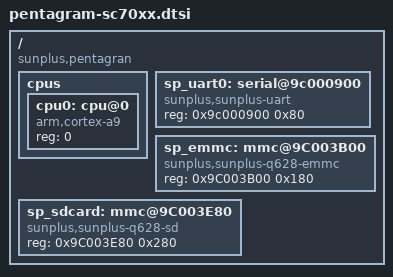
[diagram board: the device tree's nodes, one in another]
/*
 * Sunplus Pentagram sc70xx DTS
 *
 * SPDX-License-Identifier:	GPL-2.0+
 */

/ {
	#address-cells = <1>;
	#size-cells = <1>;
	compatible = "sunplus,pentagran";

	cpus {
		#address-cells = <1>;
		#size-cells = <0>;

		cpu0: cpu@0 {
			compatible = "arm,cortex-a9";
			device_type = "cpu";
			reg = <0>;
		};
	};

	sp_uart0: serial@9c000900 {
		compatible = "sunplus,sunplus-uart";
		reg = <0x9c000900 0x80>;
	};

	sp_emmc: mmc@9C003B00 {
		compatible = "sunplus,sunplus-q628-emmc";
		reg = <0x9C003B00 0x180>;
	};

	sp_sdcard: mmc@9C003E80 {
		compatible = "sunplus,sunplus-q628-sd";
		reg = <0x9C003E80 0x280>;
	};

/* 8388 sp_emmc and sp_sd0 use same pinmux, so don't enable them at the same time */
/*
    sp_emmc: mmc@9C003B00 {
        compatible = "sunplus,sunplus-q610-emmc";
        reg = <0x9C003B00 0x280>;
    };
	
*/
/*
	sp_sd0: mmc@9C003B00 {
        compatible = "sunplus,sunplus-q610-sd0";
        reg = <0x9C003B00 0x280>;
    };

*/
/*
	sp_sd1: mmc@9C003E80 {
        compatible = "sunplus,sunplus-q610-sd1";
        reg = <0x9C003E80 0x280>;
    };
*/
};
